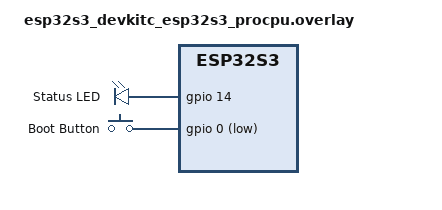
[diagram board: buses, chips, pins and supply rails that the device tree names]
/* boards/esp32s3_devkitc_esp32s3_procpu.overlay */

/ {
    /* Define physical GPIO nodes for ESP32-S3 */
    leds {
        compatible = "gpio-leds";
        led0: led_0 {
            gpios = <&gpio 14 GPIO_ACTIVE_HIGH>; /* External LED on GPIO14 */
            label = "Status LED";
        };
    };

    buttons {
        compatible = "gpio-keys";
        button0: button_0 {
            gpios = <&gpio 0 (GPIO_PULL_UP | GPIO_ACTIVE_LOW)>; /* Onboard BOOT button (GPIO0) */
            label = "Boot Button";
        };
    };

    /* Point aliases to the defined nodes */
    aliases {
        led0 = &led0;
        sw0 = &button0;
    };
};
